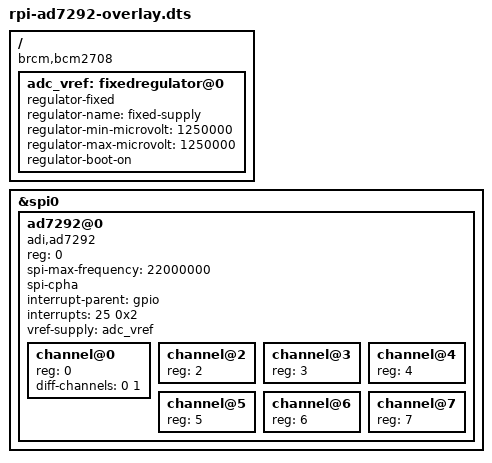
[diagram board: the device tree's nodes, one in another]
/dts-v1/;
/plugin/;

/ {
	compatible = "brcm,bcm2708";

	fragment@0 {
		target-path = "/";
		__overlay__ {
			adc_vref: fixedregulator@0 {
				compatible = "regulator-fixed";
				regulator-name = "fixed-supply";
				regulator-min-microvolt = <1250000>;
				regulator-max-microvolt = <1250000>;
				regulator-boot-on;
			};
		};
	};

	fragment@1 {
		target = <&spi0>;
		__overlay__ {
			#address-cells = <1>;
			#size-cells = <0>;
			status = "okay";

			ad7292@0{
				compatible = "adi,ad7292";
				reg = <0>;
				spi-max-frequency = <22000000>;
				spi-cpha;
				interrupt-parent = <&gpio>;
				interrupts = <25 0x2>;
				vref-supply = <&adc_vref>;

				#address-cells = <1>;
				#size-cells = <0>;

				channel@0 {
					reg = <0>;
					diff-channels = <0 1>;
				};
				channel@2 {
					reg = <2>;
				};
				channel@3 {
					reg = <3>;
				};
				channel@4 {
					reg = <4>;
				};
				channel@5 {
					reg = <5>;
				};
				channel@6 {
					reg = <6>;
				};
				channel@7 {
					reg = <7>;
				};

			};
		};
	};
};
